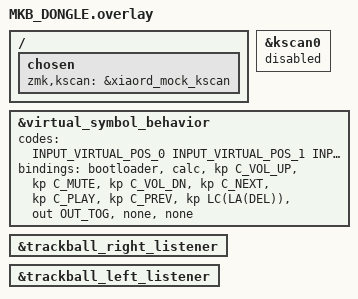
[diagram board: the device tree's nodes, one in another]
#include "MKB.dtsi"
#include <dt-bindings/xiaord/icons.h>
#include <dt-bindings/zmk/keys.h>
#include <dt-bindings/zmk/outputs.h>

&kscan0 {
    status = "disabled";
};

/ {
    chosen {
        zmk,kscan = &xiaord_mock_kscan;
    };
};

// ============================================================
// ICON_* constant definitions:
//   zmk_modules/zmk-module-xiaord/include/dt-bindings/xiaord/icons.h
// 標準アイコンからアイコンを差し替えているので
// zmk-module-xiaord内のcustom_icons.cがアイコンの本体
// ============================================================
// &home_button_0 { symbol = <ICON_>; };    /* 12 o'clock */
// &home_button_1 { symbol = <ICON_>; };     /*  1 o'clock  */
// &home_button_2 { symbol = <ICON_>; }; /*  2 o'clock */
// &home_button_3 { symbol = <ICON_>; };       /*  3 o'clock */
// &home_button_4 { symbol = <ICON_>; }; /*  4 o'clock */
// &home_button_5 { symbol = <ICON_>; };       /*  5 o'clock */
// &home_button_6 { symbol = <ICON_>; };       /*  6 o'clock */
// &home_button_7 { symbol = <ICON_>; };       /*  7 o'clock */
// &home_button_8 { symbol = <ICON_>; };    /*  8 o'clock */
// &home_button_9 { symbol = <ICON_>; };        /*  9 o'clock */
// &home_button_10 { symbol = <ICON_>; nav-page = <XIAORD_PAGE_BT>; };    /* 10 o'clock */
// &home_button_11 { symbol = <ICON_>; nav-page = <XIAORD_PAGE_CLOCK>; }; /* 11 o'clock */

&virtual_symbol_behavior {
    codes = <
        INPUT_VIRTUAL_POS_0    INPUT_VIRTUAL_POS_1
        INPUT_VIRTUAL_POS_2    INPUT_VIRTUAL_POS_3
        INPUT_VIRTUAL_POS_4    INPUT_VIRTUAL_POS_5
        INPUT_VIRTUAL_POS_6    INPUT_VIRTUAL_POS_7
        INPUT_VIRTUAL_POS_8    INPUT_VIRTUAL_POS_9
        INPUT_VIRTUAL_POS_10   INPUT_VIRTUAL_POS_11
    >;
    bindings = <
        &bootloader            &calc
        &kp C_VOL_UP           &kp C_MUTE
        &kp C_VOL_DN           &kp C_NEXT
        &kp C_PLAY             &kp C_PREV
        &kp LC(LA(DEL))        &out OUT_TOG
        &none                  &none
    >;
};

&trackball_right_listener {
  status = "okay";
};

&trackball_left_listener {
  status = "okay";
};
